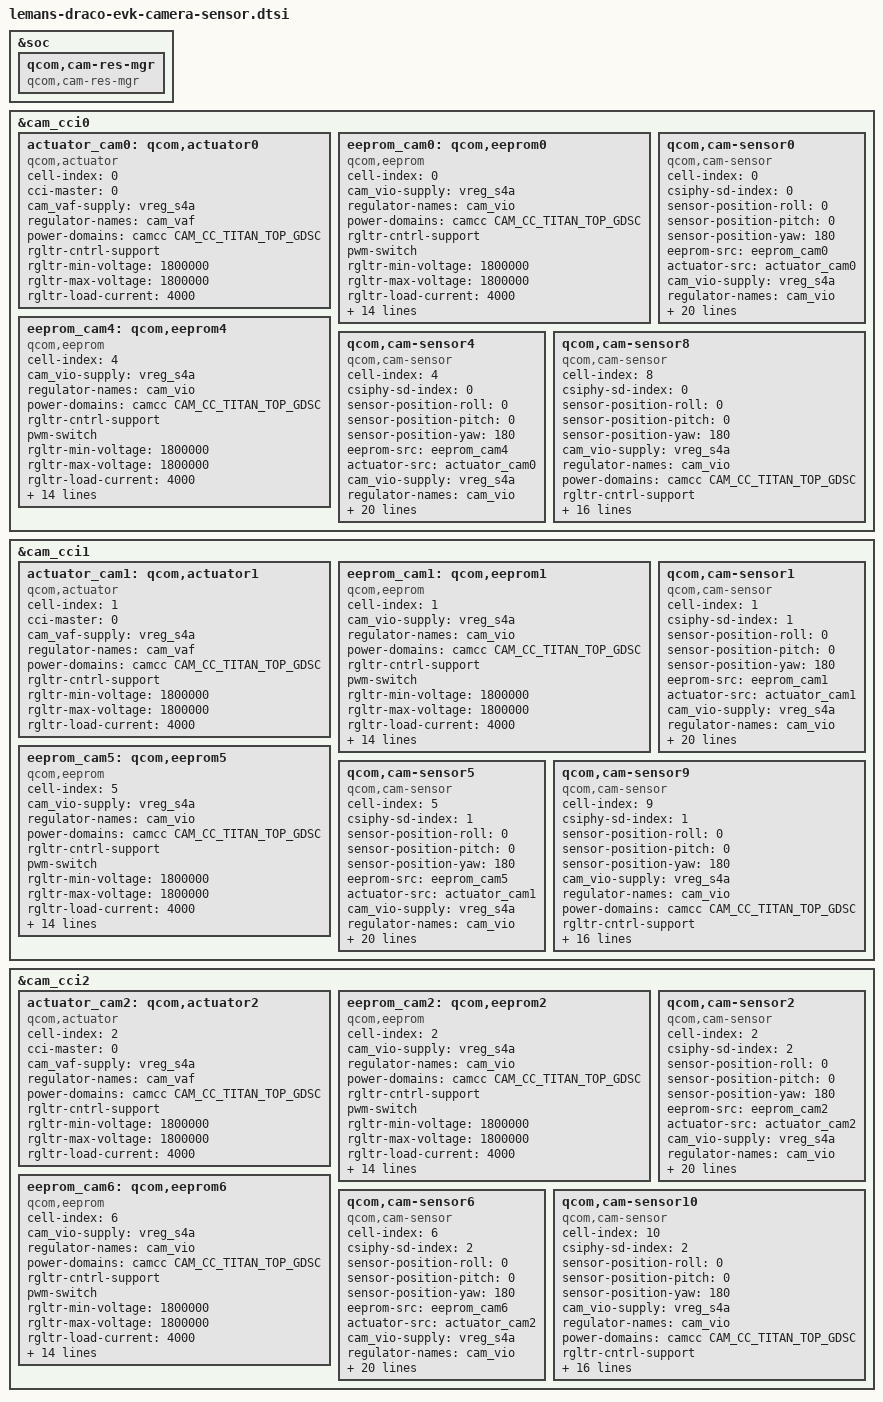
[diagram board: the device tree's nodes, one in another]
// SPDX-License-Identifier: BSD-3-Clause
/*
 * Copyright (c) Qualcomm Technologies, Inc. and/or its subsidiaries.
 */

#include <dt-bindings/camera/msm-camera.h>
#include <dt-bindings/gpio/gpio.h>

&soc {
	qcom,cam-res-mgr {
		compatible = "qcom,cam-res-mgr";
		status = "okay";
	};
};

&cam_cci0 {
	actuator_cam0: qcom,actuator0 {
		compatible = "qcom,actuator";
		cell-index = <0>;
		cci-master = <0>;
		cam_vaf-supply = <&vreg_s4a>;
		regulator-names = "cam_vaf";
		power-domains = <&camcc CAM_CC_TITAN_TOP_GDSC>;
		rgltr-cntrl-support;
		rgltr-min-voltage = <1800000>;
		rgltr-max-voltage = <1800000>;
		rgltr-load-current = <4000>;
		status = "okay";
	};

	/*EEPROM0: OV13B10*/
	eeprom_cam0: qcom,eeprom0 {
		compatible = "qcom,eeprom";
		cell-index = <0>;
		cam_vio-supply = <&vreg_s4a>;
		regulator-names = "cam_vio";
		power-domains = <&camcc CAM_CC_TITAN_TOP_GDSC>;
		rgltr-cntrl-support;
		pwm-switch;
		rgltr-min-voltage = <1800000>;
		rgltr-max-voltage = <1800000>;
		rgltr-load-current = <4000>;
		gpio-no-mux = <0>;
		pinctrl-names = "cam_default", "cam_suspend";
		pinctrl-0 = <&cam_sensor_mclk0_active>;
		pinctrl-1 = <&cam_sensor_mclk0_suspend>;
		gpios = <&tlmm 67 0>,
			<&tlmm 73 0>,
			<&expander0 1 0>;
		gpio-reset = <1>;
		gpio-custom1 = <2>;
		gpio-req-tbl-num = <0 1 2>;
		gpio-req-tbl-flags = <1 0 0>;
		gpio-req-tbl-label = "CAM_MCLK0",
		                     "CAMIF_RESET0",
		                     "CAM_CUSTOM0";
		cci-master = <0>;
		clocks = <&camcc CAM_CC_MCLK0_CLK>;
		clock-names = "cam_clk";
		clock-cntl-level = "nominal";
		clock-rates = <24000000>;
		status = "okay";
	};

	/*cam0: OV13B10*/
	qcom,cam-sensor0 {
		compatible = "qcom,cam-sensor";
		cell-index = <0>;
		csiphy-sd-index = <0>;
		sensor-position-roll = <0>;
		sensor-position-pitch = <0>;
		sensor-position-yaw = <180>;
		eeprom-src = <&eeprom_cam0>;
		actuator-src = <&actuator_cam0>;
		cam_vio-supply = <&vreg_s4a>;
		regulator-names = "cam_vio";
		power-domains = <&camcc CAM_CC_TITAN_TOP_GDSC>;
		rgltr-cntrl-support;
		pwm-switch;
		rgltr-min-voltage = <1800000>;
		rgltr-max-voltage = <1800000>;
		rgltr-load-current = <4000>;
		gpio-no-mux = <0>;
		pinctrl-names = "cam_default", "cam_suspend";
		pinctrl-0 = <&cam_sensor_mclk0_active>;
		pinctrl-1 = <&cam_sensor_mclk0_suspend>;
		gpios = <&tlmm 67 0>,
			<&tlmm 73 0>,
			<&expander0 1 0>;
		gpio-reset = <1>;
		gpio-custom1 = <2>;
		gpio-req-tbl-num = <0 1 2>;
		gpio-req-tbl-flags = <1 0 0>;
		gpio-req-tbl-label = "CAM_MCLK0",
		                     "CAMIF_RESET0",
		                     "CAM_CUSTOM0";
		cci-master = <0>;
		clocks = <&camcc CAM_CC_MCLK0_CLK>;
		clock-names = "cam_clk";
		clock-cntl-level = "nominal";
		clock-rates = <24000000>;
		status = "okay";
	};

	/*EEPROM0: IMX858*/
	eeprom_cam4: qcom,eeprom4 {
		compatible = "qcom,eeprom";
		cell-index = <4>;
		cam_vio-supply = <&vreg_s4a>;
		regulator-names = "cam_vio";
		power-domains = <&camcc CAM_CC_TITAN_TOP_GDSC>;
		rgltr-cntrl-support;
		pwm-switch;
		rgltr-min-voltage = <1800000>;
		rgltr-max-voltage = <1800000>;
		rgltr-load-current = <4000>;
		gpio-no-mux = <0>;
		pinctrl-names = "cam_default", "cam_suspend";
		pinctrl-0 = <&cam_sensor_mclk0_active>;
		pinctrl-1 = <&cam_sensor_mclk0_suspend>;
		gpios = <&tlmm 67 0>,
			<&tlmm 73 0>,
			<&expander0 1 0>;
		gpio-reset = <1>;
		gpio-custom1 = <2>;
		gpio-req-tbl-num = <0 1 2>;
		gpio-req-tbl-flags = <1 0 0>;
		gpio-req-tbl-label = "CAM_MCLK0",
		                     "CAMIF_RESET0",
		                     "CAM_CUSTOM0";
		cci-master = <0>;
		clocks = <&camcc CAM_CC_MCLK0_CLK>;
		clock-names = "cam_clk";
		clock-cntl-level = "nominal";
		clock-rates = <19200000>;
		status = "okay";
	};

	/*cam0: IMX858*/
	qcom,cam-sensor4 {
		compatible = "qcom,cam-sensor";
		cell-index = <4>;
		csiphy-sd-index = <0>;
		sensor-position-roll = <0>;
		sensor-position-pitch = <0>;
		sensor-position-yaw = <180>;
		eeprom-src = <&eeprom_cam4>;
		actuator-src = <&actuator_cam0>;
		cam_vio-supply = <&vreg_s4a>;
		regulator-names = "cam_vio";
		power-domains = <&camcc CAM_CC_TITAN_TOP_GDSC>;
		rgltr-cntrl-support;
		pwm-switch;
		rgltr-min-voltage = <1800000>;
		rgltr-max-voltage = <1800000>;
		rgltr-load-current = <4000>;
		gpio-no-mux = <0>;
		pinctrl-names = "cam_default", "cam_suspend";
		pinctrl-0 = <&cam_sensor_mclk0_active>;
		pinctrl-1 = <&cam_sensor_mclk0_suspend>;
		gpios = <&tlmm 67 0>,
			<&tlmm 73 0>,
			<&expander0 1 0>;
		gpio-reset = <1>;
		gpio-custom1 = <2>;
		gpio-req-tbl-num = <0 1 2>;
		gpio-req-tbl-flags = <1 0 0>;
		gpio-req-tbl-label = "CAM_MCLK0",
		                     "CAMIF_RESET0",
		                     "CAM_CUSTOM0";
		cci-master = <0>;
		clocks = <&camcc CAM_CC_MCLK0_CLK>;
		clock-names = "cam_clk";
		clock-cntl-level = "nominal";
		clock-rates = <19200000>;
		status = "okay";
	};
	
	/*cam0: IMX577 - 22pin connector*/
	qcom,cam-sensor8 {
		compatible = "qcom,cam-sensor";
		cell-index = <8>;
		csiphy-sd-index = <0>;
		sensor-position-roll = <0>;
		sensor-position-pitch = <0>;
		sensor-position-yaw = <180>;
		cam_vio-supply = <&vreg_s4a>;
		regulator-names = "cam_vio";
		power-domains = <&camcc CAM_CC_TITAN_TOP_GDSC>;
		rgltr-cntrl-support;
		pwm-switch;
		rgltr-min-voltage = <1800000>;
		rgltr-max-voltage = <1800000>;
		rgltr-load-current = <120000>;
		gpio-no-mux = <0>;
		pinctrl-names = "cam_default", "cam_suspend";
		pinctrl-0 = <&cam_sensor_mclk0_active>;
		pinctrl-1 = <&cam_sensor_mclk0_suspend>;
		gpios = <&tlmm 67 0>,
			<&tlmm 73 0>;
		gpio-reset = <1>;
		gpio-req-tbl-num = <0 1>;
		gpio-req-tbl-flags = <1 0>;
		gpio-req-tbl-label = "CAM_MCLK0",
		                     "CAMIF_RESET0";
		cci-master = <0>;
		clocks = <&camcc CAM_CC_MCLK0_CLK>;
		clock-names = "cam_clk";
		clock-cntl-level = "nominal";
		clock-rates = <24000000>;
		status = "okay";
	};
};

&cam_cci1 {
	actuator_cam1: qcom,actuator1 {
		compatible = "qcom,actuator";
		cell-index = <1>;
		cci-master = <0>;
		cam_vaf-supply = <&vreg_s4a>;
		regulator-names = "cam_vaf";
		power-domains = <&camcc CAM_CC_TITAN_TOP_GDSC>;
		rgltr-cntrl-support;
		rgltr-min-voltage = <1800000>;
		rgltr-max-voltage = <1800000>;
		rgltr-load-current = <4000>;
		status = "okay";
	};

	/*EEPROM1: OV13B10*/
	eeprom_cam1: qcom,eeprom1 {
		compatible = "qcom,eeprom";
		cell-index = <1>;
		cam_vio-supply = <&vreg_s4a>;
		regulator-names = "cam_vio";
		power-domains = <&camcc CAM_CC_TITAN_TOP_GDSC>;
		rgltr-cntrl-support;
		pwm-switch;
		rgltr-min-voltage = <1800000>;
		rgltr-max-voltage = <1800000>;
		rgltr-load-current = <4000>;
		gpio-no-mux = <0>;
		pinctrl-names = "cam_default", "cam_suspend";
		pinctrl-0 = <&cam_sensor_mclk1_active>;
		pinctrl-1 = <&cam_sensor_mclk1_suspend>;
		gpios = <&tlmm 68 0>,
			<&tlmm 74 0>,
			<&expander0 3 0>;
		gpio-reset = <1>;
		gpio-custom1 = <2>;
		gpio-req-tbl-num = <0 1 2>;
		gpio-req-tbl-flags = <1 0 0>;
		gpio-req-tbl-label = "CAM_MCLK1",
		                     "CAMIF_RESET1",
		                     "CAM_CUSTOM1";
		cci-master = <0>;
		clocks = <&camcc CAM_CC_MCLK1_CLK>;
		clock-names = "cam_clk";
		clock-cntl-level = "nominal";
		clock-rates = <24000000>;
		status = "okay";
	};

	/*cam1: OV13B10*/
	qcom,cam-sensor1 {
		compatible = "qcom,cam-sensor";
		cell-index = <1>;
		csiphy-sd-index = <1>;
		sensor-position-roll = <0>;
		sensor-position-pitch = <0>;
		sensor-position-yaw = <180>;
		eeprom-src = <&eeprom_cam1>;
		actuator-src = <&actuator_cam1>;
		cam_vio-supply = <&vreg_s4a>;
		regulator-names = "cam_vio";
		power-domains = <&camcc CAM_CC_TITAN_TOP_GDSC>;
		rgltr-cntrl-support;
		pwm-switch;
		rgltr-min-voltage = <1800000>;
		rgltr-max-voltage = <1800000>;
		rgltr-load-current = <4000>;
		gpio-no-mux = <0>;
		pinctrl-names = "cam_default", "cam_suspend";
		pinctrl-0 = <&cam_sensor_mclk1_active>;
		pinctrl-1 = <&cam_sensor_mclk1_suspend>;
		gpios = <&tlmm 68 0>,
			<&tlmm 74 0>,
			<&expander0 3 0>;
		gpio-reset = <1>;
		gpio-custom1 = <2>;
		gpio-req-tbl-num = <0 1 2>;
		gpio-req-tbl-flags = <1 0 0>;
		gpio-req-tbl-label = "CAM_MCLK1",
		                     "CAMIF_RESET1",
		                     "CAM_CUSTOM1";
		cci-master = <0>;
		clocks = <&camcc CAM_CC_MCLK1_CLK>;
		clock-names = "cam_clk";
		clock-cntl-level = "nominal";
		clock-rates = <24000000>;
		status = "okay";
	};

	/*EEPROM1: IMX858*/
	eeprom_cam5: qcom,eeprom5 {
		compatible = "qcom,eeprom";
		cell-index = <5>;
		cam_vio-supply = <&vreg_s4a>;
		regulator-names = "cam_vio";
		power-domains = <&camcc CAM_CC_TITAN_TOP_GDSC>;
		rgltr-cntrl-support;
		pwm-switch;
		rgltr-min-voltage = <1800000>;
		rgltr-max-voltage = <1800000>;
		rgltr-load-current = <4000>;
		gpio-no-mux = <0>;
		pinctrl-names = "cam_default", "cam_suspend";
		pinctrl-0 = <&cam_sensor_mclk1_active>;
		pinctrl-1 = <&cam_sensor_mclk1_suspend>;
		gpios = <&tlmm 68 0>,
			<&tlmm 74 0>,
			<&expander0 3 0>;
		gpio-reset = <1>;
		gpio-custom1 = <2>;
		gpio-req-tbl-num = <0 1 2>;
		gpio-req-tbl-flags = <1 0 0>;
		gpio-req-tbl-label = "CAM_MCLK1",
		                     "CAMIF_RESET1",
		                     "CAM_CUSTOM1";
		cci-master = <0>;
		clocks = <&camcc CAM_CC_MCLK1_CLK>;
		clock-names = "cam_clk";
		clock-cntl-level = "nominal";
		clock-rates = <19200000>;
		status = "okay";
	};

	/*cam1: IMX858*/
	qcom,cam-sensor5 {
		compatible = "qcom,cam-sensor";
		cell-index = <5>;
		csiphy-sd-index = <1>;
		sensor-position-roll = <0>;
		sensor-position-pitch = <0>;
		sensor-position-yaw = <180>;
		eeprom-src = <&eeprom_cam5>;
		actuator-src = <&actuator_cam1>;
		cam_vio-supply = <&vreg_s4a>;
		regulator-names = "cam_vio";
		power-domains = <&camcc CAM_CC_TITAN_TOP_GDSC>;
		rgltr-cntrl-support;
		pwm-switch;
		rgltr-min-voltage = <1800000>;
		rgltr-max-voltage = <1800000>;
		rgltr-load-current = <4000>;
		gpio-no-mux = <0>;
		pinctrl-names = "cam_default", "cam_suspend";
		pinctrl-0 = <&cam_sensor_mclk1_active>;
		pinctrl-1 = <&cam_sensor_mclk1_suspend>;
		gpios = <&tlmm 68 0>,
			<&tlmm 74 0>,
			<&expander0 3 0>;
		gpio-reset = <1>;
		gpio-custom1 = <2>;
		gpio-req-tbl-num = <0 1 2>;
		gpio-req-tbl-flags = <1 0 0>;
		gpio-req-tbl-label = "CAM_MCLK1",
		                     "CAMIF_RESET1",
		                     "CAM_CUSTOM1";
		cci-master = <0>;
		clocks = <&camcc CAM_CC_MCLK1_CLK>;
		clock-names = "cam_clk";
		clock-cntl-level = "nominal";
		clock-rates = <19200000>;
		status = "okay";
	};
	
	/*cam1: IMX577 - 22pin connector*/
	qcom,cam-sensor9 {
		compatible = "qcom,cam-sensor";
		cell-index = <9>;
		csiphy-sd-index = <1>;
		sensor-position-roll = <0>;
		sensor-position-pitch = <0>;
		sensor-position-yaw = <180>;
		cam_vio-supply = <&vreg_s4a>;
		regulator-names = "cam_vio";
		power-domains = <&camcc CAM_CC_TITAN_TOP_GDSC>;
		rgltr-cntrl-support;
		pwm-switch;
		rgltr-min-voltage = <1800000>;
		rgltr-max-voltage = <1800000>;
		rgltr-load-current = <120000>;
		gpio-no-mux = <0>;
		pinctrl-names = "cam_default", "cam_suspend";
		pinctrl-0 = <&cam_sensor_mclk1_active>;
		pinctrl-1 = <&cam_sensor_mclk1_suspend>;
		gpios = <&tlmm 68 0>,
			<&tlmm 74 0>;
		gpio-reset = <1>;
		gpio-req-tbl-num = <0 1>;
		gpio-req-tbl-flags = <1 0>;
		gpio-req-tbl-label = "CAM_MCLK1",
		                     "CAMIF_RESET1";
		cci-master = <0>;
		clocks = <&camcc CAM_CC_MCLK1_CLK>;
		clock-names = "cam_clk";
		clock-cntl-level = "nominal";
		clock-rates = <24000000>;
		status = "okay";
	};

};

&cam_cci2 {
	actuator_cam2: qcom,actuator2 {
		compatible = "qcom,actuator";
		cell-index = <2>;
		cci-master = <0>;
		cam_vaf-supply = <&vreg_s4a>;
		regulator-names = "cam_vaf";
		power-domains = <&camcc CAM_CC_TITAN_TOP_GDSC>;
		rgltr-cntrl-support;
		rgltr-min-voltage = <1800000>;
		rgltr-max-voltage = <1800000>;
		rgltr-load-current = <4000>;
		status = "okay";
	};

	/*EEPROM2: OV13B10*/
	eeprom_cam2: qcom,eeprom2 {
		compatible = "qcom,eeprom";
		cell-index = <2>;
		cam_vio-supply = <&vreg_s4a>;
		regulator-names = "cam_vio";
		power-domains = <&camcc CAM_CC_TITAN_TOP_GDSC>;
		rgltr-cntrl-support;
		pwm-switch;
		rgltr-min-voltage = <1800000>;
		rgltr-max-voltage = <1800000>;
		rgltr-load-current = <4000>;
		gpio-no-mux = <0>;
		pinctrl-names = "cam_default", "cam_suspend";
		pinctrl-0 = <&cam_sensor_mclk2_active>;
		pinctrl-1 = <&cam_sensor_mclk2_suspend>;
		gpios = <&tlmm 69 0>,
			<&tlmm 75 0>,
			<&expander0 5 0>;
		gpio-reset = <1>;
		gpio-custom1 = <2>;
		gpio-req-tbl-num = <0 1 2>;
		gpio-req-tbl-flags = <1 0 0>;
		gpio-req-tbl-label = "CAM_MCLK2",
		                     "CAMIF_RESET2",
		                     "CAM_CUSTOM2";
		cci-master = <0>;
		clocks = <&camcc CAM_CC_MCLK2_CLK>;
		clock-names = "cam_clk";
		clock-cntl-level = "nominal";
		clock-rates = <24000000>;
		status = "okay";
	};

	/*cam2: OV13B10*/
	qcom,cam-sensor2 {
		compatible = "qcom,cam-sensor";
		cell-index = <2>;
		csiphy-sd-index = <2>;
		sensor-position-roll = <0>;
		sensor-position-pitch = <0>;
		sensor-position-yaw = <180>;
		eeprom-src = <&eeprom_cam2>;
		actuator-src = <&actuator_cam2>;
		cam_vio-supply = <&vreg_s4a>;
		regulator-names = "cam_vio";
		power-domains = <&camcc CAM_CC_TITAN_TOP_GDSC>;
		rgltr-cntrl-support;
		pwm-switch;
		rgltr-min-voltage = <1800000>;
		rgltr-max-voltage = <1800000>;
		rgltr-load-current = <4000>;
		gpio-no-mux = <0>;
		pinctrl-names = "cam_default", "cam_suspend";
		pinctrl-0 = <&cam_sensor_mclk2_active>;
		pinctrl-1 = <&cam_sensor_mclk2_suspend>;
		gpios = <&tlmm 69 0>,
			<&tlmm 75 0>,
			<&expander0 5 0>;
		gpio-reset = <1>;
		gpio-custom1 = <2>;
		gpio-req-tbl-num = <0 1 2>;
		gpio-req-tbl-flags = <1 0 0>;
		gpio-req-tbl-label = "CAM_MCLK2",
		                     "CAMIF_RESET2",
		                     "CAM_CUSTOM2";
		cci-master = <0>;
		clocks = <&camcc CAM_CC_MCLK2_CLK>;
		clock-names = "cam_clk";
		clock-cntl-level = "nominal";
		clock-rates = <24000000>;
		status = "okay";
	};

	/*EEPROM2: IMX858*/
	eeprom_cam6: qcom,eeprom6 {
		compatible = "qcom,eeprom";
		cell-index = <6>;
		cam_vio-supply = <&vreg_s4a>;
		regulator-names = "cam_vio";
		power-domains = <&camcc CAM_CC_TITAN_TOP_GDSC>;
		rgltr-cntrl-support;
		pwm-switch;
		rgltr-min-voltage = <1800000>;
		rgltr-max-voltage = <1800000>;
		rgltr-load-current = <4000>;
		gpio-no-mux = <0>;
		pinctrl-names = "cam_default", "cam_suspend";
		pinctrl-0 = <&cam_sensor_mclk2_active>;
		pinctrl-1 = <&cam_sensor_mclk2_suspend>;
		gpios = <&tlmm 69 0>,
			<&tlmm 75 0>,
			<&expander0 5 0>;
		gpio-reset = <1>;
		gpio-custom1 = <2>;
		gpio-req-tbl-num = <0 1 2>;
		gpio-req-tbl-flags = <1 0 0>;
		gpio-req-tbl-label = "CAM_MCLK2",
		                     "CAMIF_RESET2",
		                     "CAM_CUSTOM2";
		cci-master = <0>;
		clocks = <&camcc CAM_CC_MCLK2_CLK>;
		clock-names = "cam_clk";
		clock-cntl-level = "nominal";
		clock-rates = <19200000>;
		status = "okay";
	};

	/*cam2: IMX858*/
	qcom,cam-sensor6 {
		compatible = "qcom,cam-sensor";
		cell-index = <6>;
		csiphy-sd-index = <2>;
		sensor-position-roll = <0>;
		sensor-position-pitch = <0>;
		sensor-position-yaw = <180>;
		eeprom-src = <&eeprom_cam6>;
		actuator-src = <&actuator_cam2>;
		cam_vio-supply = <&vreg_s4a>;
		regulator-names = "cam_vio";
		power-domains = <&camcc CAM_CC_TITAN_TOP_GDSC>;
		rgltr-cntrl-support;
		pwm-switch;
		rgltr-min-voltage = <1800000>;
		rgltr-max-voltage = <1800000>;
		rgltr-load-current = <4000>;
		gpio-no-mux = <0>;
		pinctrl-names = "cam_default", "cam_suspend";
		pinctrl-0 = <&cam_sensor_mclk2_active>;
		pinctrl-1 = <&cam_sensor_mclk2_suspend>;
		gpios = <&tlmm 69 0>,
			<&tlmm 75 0>,
			<&expander0 5 0>;
		gpio-reset = <1>;
		gpio-custom1 = <2>;
		gpio-req-tbl-num = <0 1 2>;
		gpio-req-tbl-flags = <1 0 0>;
		gpio-req-tbl-label = "CAM_MCLK2",
		                     "CAMIF_RESET2",
		                     "CAM_CUSTOM2";
		cci-master = <0>;
		clocks = <&camcc CAM_CC_MCLK2_CLK>;
		clock-names = "cam_clk";
		clock-cntl-level = "nominal";
		clock-rates = <19200000>;
		status = "okay";
	};
	
	/*cam2: IMX577 - 22pin connector*/
	qcom,cam-sensor10 {
		compatible = "qcom,cam-sensor";
		cell-index = <10>;
		csiphy-sd-index = <2>;
		sensor-position-roll = <0>;
		sensor-position-pitch = <0>;
		sensor-position-yaw = <180>;
		cam_vio-supply = <&vreg_s4a>;
		regulator-names = "cam_vio";
		power-domains = <&camcc CAM_CC_TITAN_TOP_GDSC>;
		rgltr-cntrl-support;
		pwm-switch;
		rgltr-min-voltage = <1800000>;
		rgltr-max-voltage = <1800000>;
		rgltr-load-current = <120000>;
		gpio-no-mux = <0>;
		pinctrl-names = "cam_default", "cam_suspend";
		pinctrl-0 = <&cam_sensor_mclk2_active>;
		pinctrl-1 = <&cam_sensor_mclk2_suspend>;
		gpios = <&tlmm 69 0>,
			<&tlmm 75 0>;
		gpio-reset = <1>;
		gpio-req-tbl-num = <0 1>;
		gpio-req-tbl-flags = <1 0>;
		gpio-req-tbl-label = "CAM_MCLK2",
		                     "CAMIF_RESET2";
		cci-master = <0>;
		clocks = <&camcc CAM_CC_MCLK2_CLK>;
		clock-names = "cam_clk";
		clock-cntl-level = "nominal";
		clock-rates = <24000000>;
		status = "okay";
	};
};
